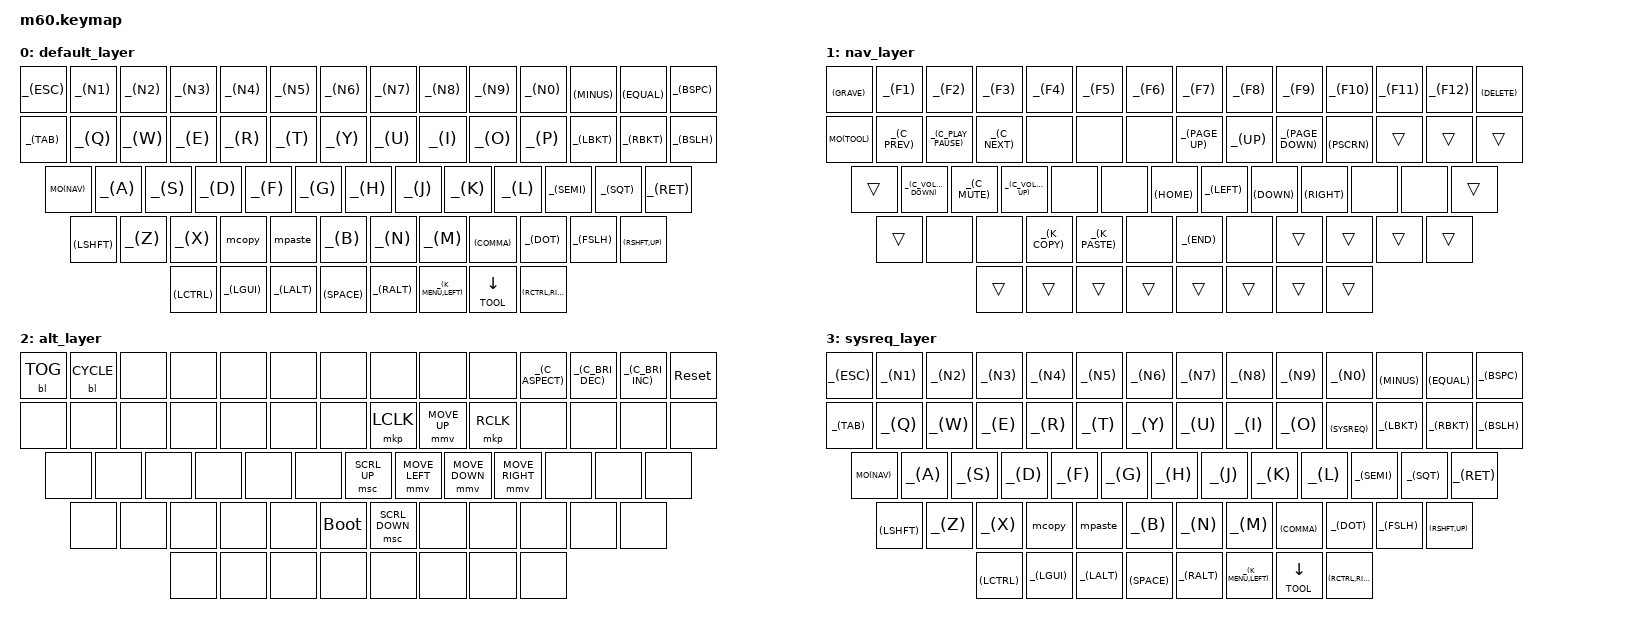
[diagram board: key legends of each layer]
/*
 * Copyright (c) 2020 The ZMK Contributors
 *
 * SPDX-License-Identifier: MIT
 */

#include <behaviors.dtsi>
#include <dt-bindings/zmk/keys.h>
#include <dt-bindings/zmk/pointing.h>
#include <dt-bindings/zmk/backlight.h>

#define none &none
#define ____ &trans

#define BASE  0
#define NAV   1
#define TOOL  2
#define SYSRQ 3

// Default key macro
#define _(KEY) &kp KEY
// Key tap macro
#define __(KEY, TAP) &mt KEY TAP
// Layer macro
#define MO(LAYER) &mo LAYER
// Define Mouse button
#define M_LCLK &mkp LCLK
#define M_RCLK &mkp RCLK
#define M_MCLK &mkp MCLK
// Define Mouse move
#define M_UP &mmv MOVE_UP
#define M_DOWN &mmv MOVE_DOWN
#define M_LEFT &mmv MOVE_LEFT
#define M_RIGHT &mmv MOVE_RIGHT
// Define Mouse scroll
#define SC_UP &msc SCRL_UP
#define SC_DOWN &msc SCRL_DOWN

/ {

  behaviors {
    mcopy: mod_copy {
      compatible = "zmk,behavior-mod-morph";
      #binding-cells = <0>;
      bindings = <&kp C>, <&kp C_AC_COPY>;
      mods = <(MOD_LGUI|MOD_RGUI)>;
    };

    mpaste: mod_paste {
      compatible = "zmk,behavior-mod-morph";
      #binding-cells = <0>;
      bindings = <&kp V>, <&kp K_PASTE>;
      mods = <(MOD_LGUI|MOD_RGUI)>;
    };

    lmt: layer_mod_tap {
      compatible = "zmk,behavior-hold-tap";
      #binding-cells = <2>;
      flavor = "hold-preferred";
      tapping-term-ms = <200>;
      bindings = <&mo>, <&kp>;
    };
  };

  keymap0: keymap {
    compatible = "zmk,keymap";

    // # layer 0 - default
    // ╭─────┬─────┬─────┬─────┬─────┬─────┬─────┬─────┬─────┬─────┬─────┬─────┬─────┬─────────╮
    // | ESC |  1  |  2  |  3  |  4  |  5  |  6  |  7  |  8  |  9  |  0  |  -  |  =  |   ⌫    |
    // |─────┴─┬───┴─┬───┴─┬───┴─┬───┴─┬───┴─┬───┴─┬───┴─┬───┴─┬───┴─┬───┴─┬───┴─┬───┴─┬───────|
    // |  ─>|  |  Q  |  W  |  E  |  R  |  T  |  Y  |  U  |  I  |  O  |  P  |  [  |  ]  |   \   |
    // |───────┴┬────┴┬────┴┬────┴┬────┴┬────┴┬────┴┬────┴┬────┴┬────┴┬────┴┬────┴┬────┴───────|
    // |  NAV   |  A  |  S  |  D  |  F  |  G  |  H  |  J  |  K  |  L  |  ;  |  '  |     ↵     |
    // |────────┴─┬───┴─┬───┴─┬───┴─┬───┴─┬───┴─┬───┴─┬───┴─┬───┴─┬───┴─┬───┴─┬───┴────────────|
    // |    ⇧     |  Z  |  X  |  C  |  V  |  B  |  N  |  M  |  ,  |  .  |  /  |       ⇧        |
    // |──────┬───┴──┬──┴──┬──┴─────┴─────┴─────┴─────┴─────┴───┬─┴─────┼─────┴┬──────┬────────|
    // | Ctrl | Win  | Alt |                                    |  Alt  | Menu | TOOL |  Ctrl  |
    // ╰──────┴──────┴─────┴────────────────────────────────────┴───────┴──────┴──────┴────────╯

    default_layer {
      bindings = <
        _(ESC) _(N1)  _(N2)  _(N3)  _(N4)  _(N5)  _(N6)  _(N7)  _(N8)  _(N9)  _(N0)  _(MINUS) _(EQUAL) _(BSPC)
        _(TAB)  _(Q)   _(W)   _(E)   _(R)   _(T)   _(Y)   _(U)   _(I)   _(O)   _(P)  _(LBKT)  _(RBKT)  _(BSLH)
        MO(NAV) _(A)   _(S)   _(D)   _(F)   _(G)   _(H)   _(J)   _(K)   _(L)  _(SEMI) _(SQT)       _(RET)
        _(LSHFT)  _(Z)   _(X)   &mcopy   &mpaste   _(B)   _(N)   _(M)  _(COMMA) _(DOT)  _(FSLH)       __(RSHFT,UP)
        _(LCTRL) _(LGUI) _(LALT)               _(SPACE)           _(RALT)  __(K_MENU,LEFT)  &lmt TOOL DOWN   __(RCTRL,RIGHT)
      >;
    };

    // # layer 1 - navigation
    // ╭─────┬─────┬─────┬─────┬─────┬─────┬─────┬─────┬─────┬─────┬─────┬─────┬─────┬─────────╮
    // |  `  | F1  | F2  | F3  | F4  | F5  | F6  | F7  | F8  | F9  | F10 | F11 | F12 |   ⌦    |
    // |─────┴─┬───┴─┬───┴─┬───┴─┬───┴─┬───┴─┬───┴─┬───┴─┬───┴─┬───┴─┬───┴─┬───┴─┬───┴─┬───────|
    // | TOOL  | ⏮  | ⏯  | ⏭  |     |     |     |  ⇞  |  ↑  |  ⇟  |PRINT|     |     |       |
    // |───────┴┬────┴┬────┴┬────┴┬────┴┬────┴┬────┴┬────┴┬────┴┬────┴┬────┴┬────┴┬────┴───────|
    // |        |  🕩 | 🔇 | 🕪  |     |     | ⇤  | ←  |  ↓  |  → |     |     |     ↵     |
    // |────────┴─┬───┴─┬───┴─┬───┴─┬───┴─┬───┴─┬───┴─┬───┴─┬───┴─┬───┴─┬───┴─┬───┴────────────|
    // |     ⇧    |     |     |COPY |PASTE|     |  ⇥ |     |     |     |     |       ⇧        |
    // |──────┬───┴──┬──┴──┬──┴─────┴─────┴─────┴─────┴─────┴───┬─┴─────┼─────┴┬──────┬────────|
    // | Ctrl | Win  | alt |                                    |  alt  | Menu | TOOL |  Ctrl  |
    // ╰──────┴──────┴─────┴────────────────────────────────────┴───────┴──────┴──────┴────────╯

    nav_layer {
      bindings = <
        _(GRAVE)  _(F1)  _(F2)  _(F3)  _(F4)  _(F5)  _(F6)  _(F7)  _(F8)  _(F9)  _(F10)  _(F11)  _(F12) _(DELETE)
        MO(TOOL)     _(C_PREV) _(C_PLAY_PAUSE) _(C_NEXT)  none  none  none  _(PAGE_UP)  _(UP)  _(PAGE_DOWN)  _(PSCRN)  ____  ____  ____
        ____     _(C_VOLUME_DOWN)  _(C_MUTE) _(C_VOLUME_UP) none none  _(HOME) _(LEFT) _(DOWN)   _(RIGHT)  none   none  ____
        ____     none      none      _(K_COPY)      _(K_PASTE)      none      _(END)      none      ____      ____      ____      ____
        ____       ____       ____       ____                                              ____     ____     ____     ____
      >;
    };

    // # layer 2 - Tools and bootloader
    // ╭─────┬─────┬─────┬─────┬─────┬─────┬─────┬─────┬─────┬─────┬─────┬─────┬─────┬─────────╮
    // | 💡 |     |     |     |     |     |     |     |     |     |  🖵 | 🔅 |  🔆 |  RESET  |
    // |─────┴─┬───┴─┬───┴─┬───┴─┬───┴─┬───┴─┬───┴─┬───┴─┬───┴─┬───┴─┬───┴─┬───┴─┬───┴─┬───────|
    // |       |  ‹  | 🖱️↑ |  ›  |     |     |     |  ‹ | 🖱️↑ |  ›  |     |     |     |       |
    // |───────┴┬────┴┬────┴┬────┴┬────┴┬────┴┬────┴┬────┴┬────┴┬────┴┬────┴┬────┴┬────┴───────|
    // |        |🖱️← |🖱️↓ |🖱️→ |     |     |  ↟  |🖱️←| 🖱️↓ |🖱️→|     |     |            |
    // |────────┴─┬───┴─┬───┴─┬───┴─┬───┴─┬───┴─┬───┴─┬───┴─┬───┴─┬───┴─┬───┴─┬───┴────────────|
    // |          |     |     |     |     | 🥾  |  ↡  |     |     |     |     |                |
    // |──────┬───┴──┬──┴──┬──┴─────┴─────┴─────┴─────┴─────┴───┬─┴─────┼─────┴┬──────┬────────|
    // |      |      |     |                                    |       |      |      |        |
    // ╰──────┴──────┴─────┴────────────────────────────────────┴───────┴──────┴──────┴────────╯

    alt_layer {
      bindings = <
        &bl BL_TOG &bl BL_CYCLE none none none none none none none none _(C_ASPECT) _(C_BRI_DEC) _(C_BRI_INC) &sys_reset
        none none none none none none none M_LCLK M_UP M_RCLK none none none none
        none none none none none none SC_UP M_LEFT M_DOWN M_RIGHT none none none
        none none none none none &bootloader SC_DOWN none none none none none
        none none none           none             none none none none
      >;
    };

    // # layer 3 - SYSREQ
    // ╭─────┬─────┬─────┬─────┬─────┬─────┬─────┬─────┬─────┬─────┬─────┬─────┬─────┬─────────╮
    // | ESC |  1  |  2  |  3  |  4  |  5  |  6  |  7  |  8  |  9  |  0  |  -  |  =  |   ⌫    |
    // |─────┴─┬───┴─┬───┴─┬───┴─┬───┴─┬───┴─┬───┴─┬───┴─┬───┴─┬───┴─┬───┴─┬───┴─┬───┴─┬───────|
    // |  ─>|  |  Q  |  W  |  E  |  R  |  T  |  Y  |  U  |  I  |  O  |SYSRQ|  [  |  ]  |   \   |
    // |───────┴┬────┴┬────┴┬────┴┬────┴┬────┴┬────┴┬────┴┬────┴┬────┴┬────┴┬────┴┬────┴───────|
    // |  NAV   |  A  |  S  |  D  |  F  |  G  |  H  |  J  |  K  |  L  |  ;  |  '  |     ↵     |
    // |────────┴─┬───┴─┬───┴─┬───┴─┬───┴─┬───┴─┬───┴─┬───┴─┬───┴─┬───┴─┬───┴─┬───┴────────────|
    // |    ⇧     |  Z  |  X  |  C  |  V  |  B  |  N  |  M  |  ,  |  .  |  /  |       ⇧        |
    // |──────┬───┴──┬──┴──┬──┴─────┴─────┴─────┴─────┴─────┴───┬─┴─────┼─────┴┬──────┬────────|
    // | Ctrl | Win  | alt |                                    |  alt  | MENU | TOOL |  Ctrl  |
    // ╰──────┴──────┴─────┴────────────────────────────────────┴───────┴──────┴──────┴────────╯

    sysreq_layer {
      bindings = <
        _(ESC) _(N1)  _(N2)  _(N3)  _(N4)  _(N5)  _(N6)  _(N7)  _(N8)  _(N9)  _(N0)  _(MINUS) _(EQUAL) _(BSPC)
        _(TAB)  _(Q)   _(W)   _(E)   _(R)   _(T)   _(Y)   _(U)   _(I)   _(O)  _(SYSREQ) _(LBKT)  _(RBKT)  _(BSLH)
        MO(NAV) _(A)   _(S)   _(D)   _(F)   _(G)   _(H)   _(J)   _(K)   _(L)  _(SEMI) _(SQT)       _(RET)
        _(LSHFT)  _(Z)   _(X)   &mcopy   &mpaste   _(B)   _(N)   _(M)  _(COMMA) _(DOT)  _(FSLH)       __(RSHFT,UP)
        _(LCTRL) _(LGUI) _(LALT)               _(SPACE)           _(RALT)  __(K_MENU,LEFT)  &lmt TOOL DOWN   __(RCTRL,RIGHT)
      >;
    };
  };
};
